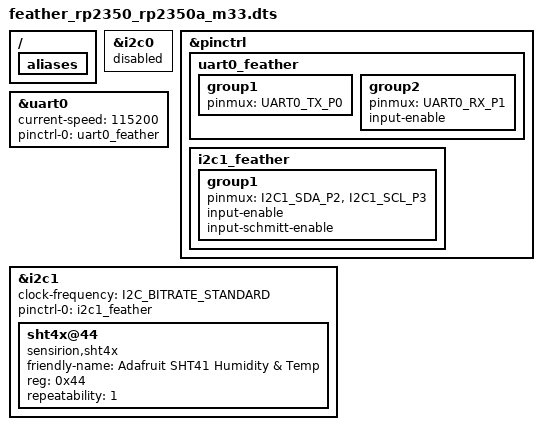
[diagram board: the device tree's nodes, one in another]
/* SPDX-License-Identifier: Apache-2.0 OR MIT */
/* SPDX-FileCopyrightText: Copyright 2025 Sam Blenny */

/* For addresses, registers, flash partition table info, etc refer to the
 * Raspberry Pi RP2350 datasheet:
 * https://datasheets.raspberrypi.com/rp2350/rp2350-datasheet.pdf
 *
 * Datasheet notes:
 * - Section 4.1: boot rom is 32kB starting at 0x00000000
 * - Section 5.1: Bootroom Concepts
 * - Section 5.1.2: Partition Tables
 * - Section 5.1.4: Image Definitions (purpose of .image_def partition)
 * See also:
 * https://docs.zephyrproject.org/latest/build/dts/api/bindings/mtd/fixed-partitions.html
 */


/* 1. Start with the Pi Pico 2 devicetree config.
 */
#include "../../../zephyr/boards/raspberrypi/rpi_pico2/rpi_pico2_rp2350a_m33.dts"


/* 2. Remove unsuitable nodes and properties for Pico 2 board pinout.
 */
/ {
	aliases {
		/delete-property/ led0;
		/delete-property/ pwm-led0;
	};
	/delete-node/ connector;
	/delete-node/ led_0;
	/delete-node/ pwm_led_0;
};
&i2c0 {
	status = "disabled";
};


/* 3. Add config for Feather RP2350 board pinout.
 *    See:
 *    - zephyr/include/zephyr/dt-bindings/pinctrl/rpi-pico-pinctrl-common.h
 *    - zephyr/include/zephyr/dt-bindings/pinctrl/rpi-pico-rp2350-pinctrl-common.h
 *    - zephyr/include/zephyr/dt-bindings/pinctrl/rpi-pico-rp2350a-pinctrl.h
 *    for definitions of UART0_TX_P0, UART0_RX_P1, etc.
 */
&pinctrl {
	uart0_feather: uart0_feather {
		group1 {
			pinmux = <UART0_TX_P0>;
		};
		group2 {
			pinmux = <UART0_RX_P1>;
			input-enable;
		};
	};
	i2c1_feather: i2c1_feather {
		group1 {
			pinmux = <I2C1_SDA_P2>, <I2C1_SCL_P3>;
			input-enable;
			input-schmitt-enable;
		};
	};
};

&uart0 {
	current-speed = <115200>;
	pinctrl-0 = <&uart0_feather>;
	pinctrl-names = "default";
	status = "okay";
};

&i2c1 {
	clock-frequency = <I2C_BITRATE_STANDARD>;
	pinctrl-0 = <&i2c1_feather>;
	pinctrl-names = "default";
	status = "okay";

	sht4x@44 {
		compatible = "sensirion,sht4x";
		friendly-name = "Adafruit SHT41 Humidity & Temp";
		reg = <0x44>;
		repeatability = <1>;
		status = "okay";
	};
};
